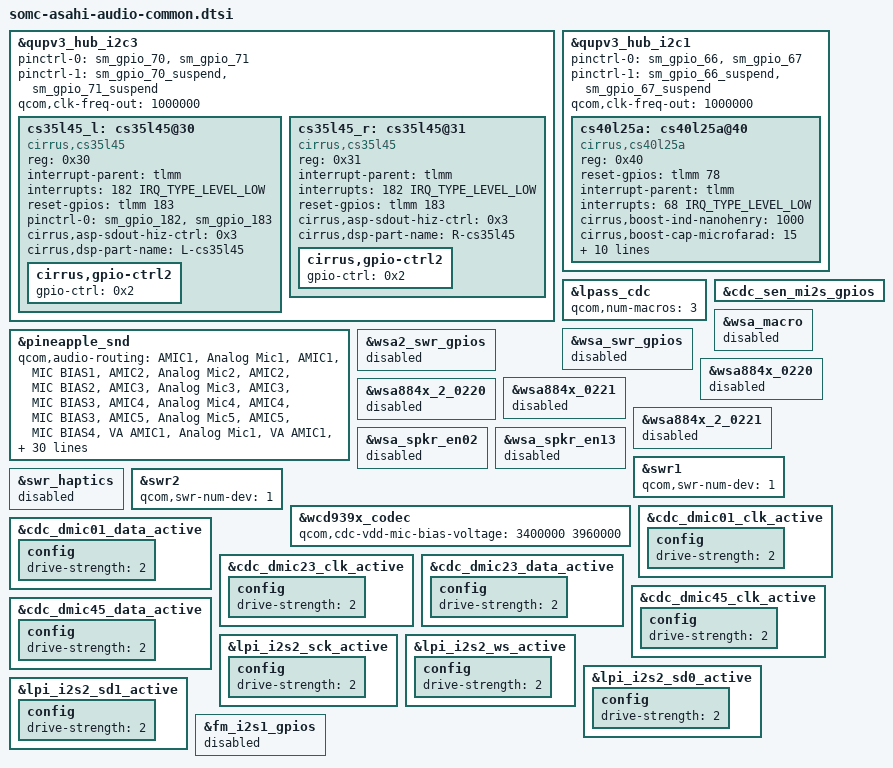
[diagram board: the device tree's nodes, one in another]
&qupv3_hub_i2c3 {
	pinctrl-0 = <&sm_gpio_70 &sm_gpio_71>;
	pinctrl-1 = <&sm_gpio_70_suspend &sm_gpio_71_suspend>;
	qcom,clk-freq-out = <1000000>;
	status = "okay";

	cs35l45_l: cs35l45@30 {
		compatible = "cirrus,cs35l45";
		reg = <0x30>;
		interrupt-parent = <&tlmm>;
		interrupts = <182 IRQ_TYPE_LEVEL_LOW>;
		reset-gpios = <&tlmm 183 0>;		/*GPIO_ACTIVE_HIGH = 0*/
		pinctrl-names = "default";
		pinctrl-0 = <&sm_gpio_182>, <&sm_gpio_183>;
		cirrus,asp-sdout-hiz-ctrl = <0x3>;
		cirrus,dsp-part-name = "L-cs35l45";
		cirrus,gpio-ctrl2 {
			gpio-ctrl = <0x2>;
		};
	};

	cs35l45_r: cs35l45@31 {
		compatible = "cirrus,cs35l45";
		reg = <0x31>;
		interrupt-parent = <&tlmm>;
		interrupts = <182 IRQ_TYPE_LEVEL_LOW>;
		reset-gpios = <&tlmm 183 0>;		/*GPIO_ACTIVE_HIGH = 0*/
		cirrus,asp-sdout-hiz-ctrl = <0x3>;
		cirrus,dsp-part-name = "R-cs35l45";
		cirrus,gpio-ctrl2 {
			gpio-ctrl = <0x2>;
		};
	};
};

&qupv3_hub_i2c1 {
	pinctrl-0 = <&sm_gpio_66 &sm_gpio_67>;
	pinctrl-1 = <&sm_gpio_66_suspend &sm_gpio_67_suspend>;
	qcom,clk-freq-out = <1000000>;
	status = "okay";

	cs40l25a: cs40l25a@40 {
		compatible = "cirrus,cs40l25a";
		reg = <0x40>;
		reset-gpios = <&tlmm 78 0>;		/*GPIO_ACTIVE_HIGH = 0*/
		interrupt-parent = <&tlmm>;
		interrupts = <68 IRQ_TYPE_LEVEL_LOW>;
		cirrus,boost-ind-nanohenry = <1000>;
		cirrus,boost-cap-microfarad = <15>;
		cirrus,boost-ipk-milliamp = <3500>;
		cirrus,hiber-enable;
		cirrus,fw-id-remap = <0x1400D0>;
		cirrus,f0-default = <2768896>;
		cirrus,f0-min = <2605056>;
		cirrus,f0-max = <2932736>;
		cirrus,redc-default = <355821>;
		cirrus,redc-min = <302112>;
		cirrus,redc-max = <409530>;
		cirrus,auto-recovery;
	};
};

&lpass_cdc {
	qcom,num-macros = <3>;
};

&pineapple_snd{
	qcom,audio-routing =
		"AMIC1", "Analog Mic1",
		"AMIC1", "MIC BIAS1",
		"AMIC2", "Analog Mic2",
		"AMIC2", "MIC BIAS2",
		"AMIC3", "Analog Mic3",
		"AMIC3", "MIC BIAS3",
		"AMIC4", "Analog Mic4",
		"AMIC4", "MIC BIAS3",
		"AMIC5", "Analog Mic5",
		"AMIC5", "MIC BIAS4",
		"VA AMIC1", "Analog Mic1",
		"VA AMIC1", "VA MIC BIAS1",
		"VA AMIC2", "Analog Mic2",
		"VA AMIC2", "VA MIC BIAS2",
		"VA AMIC3", "Analog Mic3",
		"VA AMIC3", "VA MIC BIAS3",
		"VA AMIC4", "Analog Mic4",
		"VA AMIC4", "VA MIC BIAS3",
		"VA AMIC5", "Analog Mic5",
		"VA AMIC5", "VA MIC BIAS4",
		"TX DMIC1", "Digital Mic1",
		"TX DMIC1", "MIC BIAS1",
		"TX DMIC3", "Digital Mic3",
		"TX DMIC3", "MIC BIAS3",
		"TX DMIC5", "Digital Mic5",
		"TX DMIC5", "MIC BIAS4",
		"IN1_HPHL", "HPHL_OUT",
		"IN2_HPHR", "HPHR_OUT",
		"IN3_EAR", "AUX_OUT",
		"RX_TX DEC0_INP", "TX DEC0 MUX",
		"RX_TX DEC1_INP", "TX DEC1 MUX",
		"RX_TX DEC2_INP", "TX DEC2 MUX",
		"RX_TX DEC3_INP", "TX DEC3 MUX",
		"TX SWR_INPUT", "WCD_TX_OUTPUT",
		"VA SWR_INPUT", "VA_SWR_CLK",
		"VA SWR_INPUT", "WCD_TX_OUTPUT",
		"VA_AIF1 CAP", "VA_SWR_CLK",
		"VA_AIF2 CAP", "VA_SWR_CLK",
		"VA_AIF3 CAP", "VA_SWR_CLK",
		"VA DMIC1", "Digital Mic1",
		"VA DMIC3", "Digital Mic3",
		"VA DMIC5", "Digital Mic5",
		"VA DMIC1", "VA MIC BIAS1",
		"VA DMIC3", "VA MIC BIAS3",
		"VA DMIC5", "VA MIC BIAS4";

	qcom,msm-mbhc-usbc-audio-supported = <0>;
	qcom,msm-mbhc-hphl-swh = <1>;
	qcom,msm-mbhc-gnd-swh = <1>;

	asoc-codec  = <&stub_codec>, <&lpass_cdc>,
			<&cs35l45_l>, <&cs35l45_r>,
			<&wcd939x_codec>;
	asoc-codec-names = "msm-stub-codec.1", "lpass-cdc",
				"cs35l45_l", "cs35l45_r",
				"wcd939x_codec";
	qcom,wsa-max-devs = <0>;
	qcom,sen-mi2s-gpios = <&cdc_sen_mi2s_gpios>;
};

&cdc_sen_mi2s_gpios {
	status = "okay";
};

&wsa_macro {
	status = "disabled";
};

&wsa_swr_gpios {
	status = "disabled";
};

&wsa2_swr_gpios {
	status = "disabled";
};

&wsa884x_0220 {
	status = "disabled";
};

&wsa884x_0221 {
	status = "disabled";
};

&wsa884x_2_0220 {
	status = "disabled";
};

&wsa884x_2_0221 {
	status = "disabled";
};

&wsa_spkr_en02 {
	status = "disabled";
};

&wsa_spkr_en13 {
	status = "disabled";
};

&swr1 {
	qcom,swr-num-dev = <1>;
};

&swr_haptics {
	status = "disabled";
};

&swr2 {
	qcom,swr-num-dev = <1>;
};

&wcd939x_codec {
	qcom,cdc-vdd-mic-bias-voltage = <3400000 3960000>;
};

&cdc_dmic01_clk_active  {
	config {
		drive-strength = <2>;
	};
};

&cdc_dmic01_data_active {
	config {
		drive-strength = <2>;
	};
};

&cdc_dmic23_clk_active {
	config {
		drive-strength = <2>;
	};
};

&cdc_dmic23_data_active {
	config {
		drive-strength = <2>;
	};
};

&cdc_dmic45_clk_active {
	config {
		drive-strength = <2>;
	};
};

&cdc_dmic45_data_active {
	config {
		drive-strength = <2>;
	};
};

&lpi_i2s2_sck_active {
	config {
		drive-strength = <2>;
	};
};

&lpi_i2s2_ws_active {
	config {
		drive-strength = <2>;
	};
};

&lpi_i2s2_sd0_active {
	config {
		drive-strength = <2>;
	};
};

&lpi_i2s2_sd1_active {
	config {
		drive-strength = <2>;
	};
};

&fm_i2s1_gpios {
	status = "disabled";
};
